# ATmega324PB device description
Architecture: AVR8; Family: megaAVR
Registers are 8-bit, access not given, no defined reset value unless marked. A register's access mark holds for its fields unless they carry their own. Offsets are from the block's base; [hi:lo] are bit positions; {n}, {i} and the like mark numbered series.

## TC2 (TC8_ASYNC module) — Timer/Counter, 8-bit Async
Instances: TC2 0x00
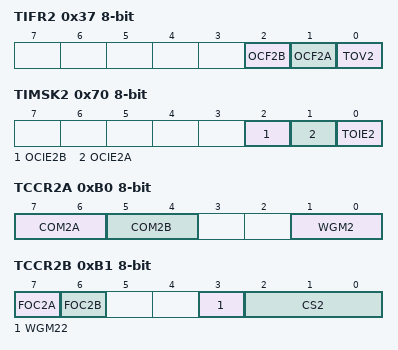
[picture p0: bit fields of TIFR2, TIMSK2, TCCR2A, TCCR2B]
0x37 TIFR2 — Timer/Counter Interrupt Flag Register
  [2] OCF2B — Output Compare Flag 2B
  [1] OCF2A — Output Compare Flag 2A
  [0] TOV2 — Timer/Counter2 Overflow Flag
0x70 TIMSK2 — Timer/Counter Interrupt Mask register
  [2] OCIE2B — Timer/Counter2 Output Compare Match B Interrupt Enable
  [1] OCIE2A — Timer/Counter2 Output Compare Match A Interrupt Enable
  [0] TOIE2 — Timer/Counter2 Overflow Interrupt Enable
0xB0 TCCR2A — Timer/Counter2 Control Register A
  [7:6] COM2A — Compare Output Mode 2A bits
  [5:4] COM2B — Compare Output Mode 2B bits
  [1:0] WGM2 — Waveform Genration Mode
0xB1 TCCR2B — Timer/Counter2 Control Register B
  [7] FOC2A — Force Output Compare A
  [6] FOC2B — Force Output Compare B
  [3] WGM22 — Waveform Generation Mode
  [2:0] CS2 — Clock Select bits
    0=No Clock Source (Stopped); 1=Running, No Prescaling; 2=Running, CLK/8; 3=Running, CLK/32; 4=Running, CLK/64; 5=Running, CLK/128; 6=Running, CLK/256; 7=Running, CLK/1024
0xB2 TCNT2 — Timer/Counter2
0xB3 OCR2A — Timer/Counter2 Output Compare Register A
0xB4 OCR2B — Timer/Counter2 Output Compare Register B
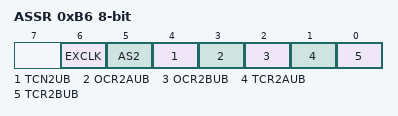
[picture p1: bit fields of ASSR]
0xB6 ASSR — Asynchronous Status Register
  [6] EXCLK — Enable External Clock Input
  [5] AS2 — Asynchronous Timer/Counter2
  [4] TCN2UB — Timer/Counter2 Update Busy
  [3] OCR2AUB — Output Compare Register2 Update Busy
  [2] OCR2BUB — Output Compare Register 2 Update Busy
  [1] TCR2AUB — Timer/Counter Control Register2 Update Busy
  [0] TCR2BUB — Timer/Counter Control Register2 Update Busy

## WDT — Watchdog Timer
Instances: WDT 0x00
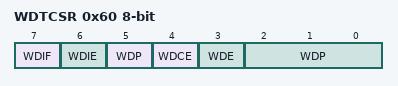
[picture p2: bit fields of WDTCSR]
0x60 WDTCSR — Watchdog Timer Control Register
  [7] WDIF — Watchdog Timeout Interrupt Flag
  [6] WDIE — Watchdog Timeout Interrupt Enable
  [4] WDCE — Watchdog Change Enable
  [3] WDE — Watch Dog Enable
  [5,2:0] WDP — Watchdog Timer Prescaler Bits
    0=Oscillator Cycles 2K; 1=Oscillator Cycles 4K; 2=Oscillator Cycles 8K; 3=Oscillator Cycles 16K; 4=Oscillator Cycles 32K; 5=Oscillator Cycles 64K; 6=Oscillator Cycles 128K; 7=Oscillator Cycles 256K; 8=Oscillator Cycles 512K; 9=Oscillator Cycles 1024K

## JTAG — JTAG Interface
Instances: JTAG 0x00
0x51 OCDR — On-Chip Debug Related Register in I/O Memory
0x54 MCUSR — MCU Status Register
  [4] JTRF — JTAG Reset Flag
0x55 MCUCR — MCU Control Register
  [7] JTD — JTAG Interface Disable

## EXINT — External Interrupts
Instances: EXINT 0x00
0x3B PCIFR — Pin Change Interrupt Flag Register
  [4:0] PCIF — Pin Change Interrupt Flags
0x3C EIFR — External Interrupt Flag Register
  [2:0] INTF — External Interrupt Flags
0x3D EIMSK — External Interrupt Mask Register
  [2:0] INT — External Interrupt Request Enable
0x68 PCICR — Pin Change Interrupt Control Register
  [4:0] PCIE — Pin Change Interrupt Enables
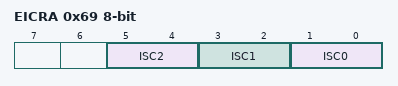
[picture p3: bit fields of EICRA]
0x69 EICRA — External Interrupt Control Register A
  [all] fields
    0=Low Level of INTX; 1=Any Logical Change of INTX; 2=Falling Edge of INTX; 3=Rising Edge of INTX
  [5:4] ISC2 — External Interrupt Sense Control Bit
  [3:2] ISC1 — External Interrupt Sense Control Bit
  [1:0] ISC0 — External Interrupt Sense Control Bit
0x6B PCMSK0 — Pin Change Mask Register 0
  [7:0] PCINT — Pin Change Enable Masks
0x6C PCMSK1 — Pin Change Mask Register 1
  [7:0] PCINT (bit 8 of the value upward) — Pin Change Enable Masks
0x6D PCMSK2 — Pin Change Mask Register 2
  [7:0] PCINT (bit 16 of the value upward) — Pin Change Enable Masks
0x73 PCMSK3 — Pin Change Mask Register 3
  [7:0] PCINT (bit 24 of the value upward) — Pin Change Enable Masks
0x75 PCMSK4 — Pin Change Mask Register 4
  [6:0] PCINT (bit 32 of the value upward) — Pin Change Enable Masks

## ADC — Analog-to-Digital Converter
Instances: ADC 0x00
0x78 ADC 16-bit — ADC Data Register Bytes
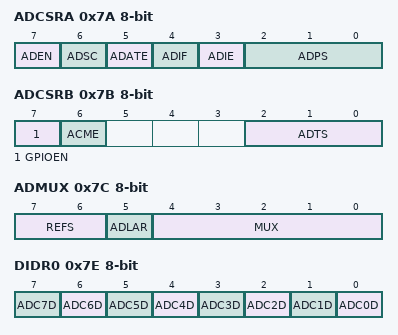
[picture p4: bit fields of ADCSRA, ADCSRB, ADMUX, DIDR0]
0x7A ADCSRA — ADC Control and Status register A
  [7] ADEN — ADC Enable
  [6] ADSC — ADC Start Conversion
  [5] ADATE — ADC Auto Trigger Enable
  [4] ADIF — ADC Interrupt Flag
  [3] ADIE — ADC Interrupt Enable
  [2:0] ADPS — ADC Prescaler Select Bits
    0=2; 1=2; 2=4; 3=8; 4=16; 5=32; 6=64; 7=128
0x7B ADCSRB — ADC Control and Status register B
  [7] GPIOEN — Enable GPIO function of PE4
  [6] ACME — Analog Comparator Multiplexer Enable
  [2:0] ADTS — ADC Auto Trigger Source bits
    0=Free Running mode; 1=Analog Comparator; 2=External Interrupt Request 0; 3=Timer/Counter0 Compare Match A; 4=Timer/Counter0 Overflow; 5=Timer/Counter1 Compare Match B; 6=Timer/Counter1 Overflow; 7=Timer/Counter1 Capture Event
0x7C ADMUX — ADC multiplexer Selection Register
  [7:6] REFS — Reference Selection Bits
    0=AREF, Internal Vref turned off; 1=AVCC with external capacitor at AREF pin; 2=Internal 1.1V Voltage Reference with external capacitor at AREF pin; 3=Internal 2.56V Voltage Reference with external capacitor at AREF pin
  [5] ADLAR — Left Adjust Result
  [4:0] MUX — Analog Channel and Gain Selection Bits
    {v}=ADC{v} (ADC Single Ended Input pin {v}) (v=0..7); 8=ADC0_ADC0_10X (ADC Differential Inputs Postive pin 0 Negative pin 0 10x Gain); 9=ADC1_ADC0_10X (ADC Differential Inputs Postive pin 1 Negative pin 0 10x Gain); 10=ADC0_ADC0_200x (ADC Differential Inputs Postive pin 0 Negative pin 0 200x Gain); 11=ADC1_ADC0_200X (ADC Differential Inputs Postive pin 1 Negative pin 0 200x Gain); 12=ADC2_ADC2_10X (ADC Differential Inputs Postive pin 2 Negative pin 2 10x Gain); 13=ADC3_ADC2_10X (ADC Differential Inputs Postive pin 3 Negative pin 2 10x Gain); 14=ADC2_ADC2_200X (ADC Differential Inputs Postive pin 2 Negative pin 2 200x Gain); 15=ADC3_ADC2_200X (ADC Differential Inputs Postive pin 3 Negative pin 2 200x Gain); {v}=ADC{v-16}_ADC1_1X (ADC Differential Inputs Postive pin {v-16} Negative pin 1 1x Gain) (v=16..23); {v}=ADC{v-24}_ADC2_1X (ADC Differential Inputs Postive pin {v-24} Negative pin 2 1x Gain) (v=24..29); 30=ADC_VBG (Internal Reference (VBG)); 31=ADC_GND (0V (GND))
0x7E DIDR0 — Digital Input Disable Register
  [n] ADC{n}D (n=0..7)
